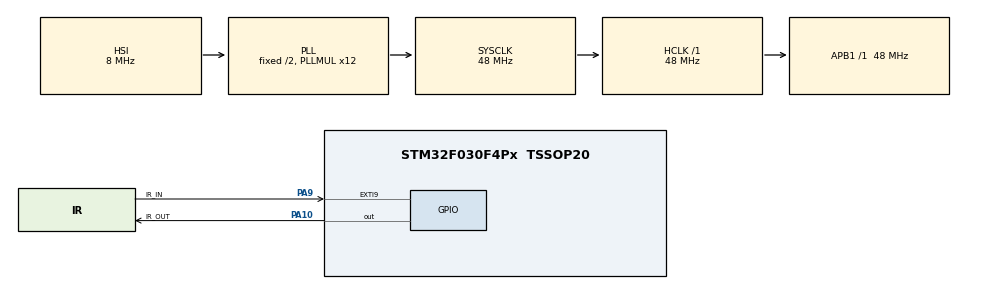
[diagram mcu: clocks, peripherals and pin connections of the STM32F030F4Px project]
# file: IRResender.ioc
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Mcu.Family=STM32F0
Mcu.Name=STM32F030F4Px
Mcu.Package=TSSOP20
NVIC.EXTI4_15_IRQn=true\:0\:0\:false\:false\:false\:true
NVIC.TIM14_IRQn=true\:0\:0\:false\:false\:false\:true
PA10.GPIO_Label=IR_OUT
PA10.GPIO_PuPd=GPIO_PULLUP
PA10.PinState=GPIO_PIN_SET
PA10.Signal=GPIO_Output
PA9.GPIO_Label=IR_IN
PA9.GPIO_ModeDefaultEXTI=GPIO_MODE_IT_RISING_FALLING
PA9.GPIO_PuPd=GPIO_PULLUP
PA9.Signal=GPXTI9
ProjectManager.HeapSize=0x200
ProjectManager.StackSize=0x400
ProjectManager.TargetToolchain=EWARM
RCC.AHBFreq_Value=48000000
RCC.APB1Freq_Value=48000000
RCC.APB1TimFreq_Value=48000000
RCC.HCLKFreq_Value=48000000
RCC.PLLMUL=RCC_PLL_MUL12
RCC.SYSCLKFreq_VALUE=48000000
RCC.SYSCLKSource=RCC_SYSCLKSOURCE_PLLCLK
TIM14.Period=3
TIM14.Prescaler=23
VP_TIM14_VS_ClockSourceINT.Mode=Enable_Timer
board=IRResender

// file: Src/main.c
/**
  ******************************************************************************
  * @file           : main.c
  * @brief          : Main program body
  ******************************************************************************
  ** This notice applies to any and all portions of this file
  * that are not between comment pairs USER CODE BEGIN and
  * USER CODE END. Other portions of this file, whether
  * inserted by the user or by software development tools
  * are owned by their respective copyright owners.
  *
  * COPYRIGHT(c) 2018 STMicroelectronics
  *
  * Redistribution and use in source and binary forms, with or without modification,
  * are permitted provided that the following conditions are met:
  *   1. Redistributions of source code must retain the above copyright notice,
  *      this list of conditions and the following disclaimer.
  *   2. Redistributions in binary form must reproduce the above copyright notice,
  *      this list of conditions and the following disclaimer in the documentation
  *      and/or other materials provided with the distribution.
  *   3. Neither the name of STMicroelectronics nor the names of its contributors
  *      may be used to endorse or promote products derived from this software
  *      without specific prior written permission.
  *
  * THIS SOFTWARE IS PROVIDED BY THE COPYRIGHT HOLDERS AND CONTRIBUTORS "AS IS"
  * AND ANY EXPRESS OR IMPLIED WARRANTIES, INCLUDING, BUT NOT LIMITED TO, THE
  * IMPLIED WARRANTIES OF MERCHANTABILITY AND FITNESS FOR A PARTICULAR PURPOSE ARE
  * DISCLAIMED. IN NO EVENT SHALL THE COPYRIGHT HOLDER OR CONTRIBUTORS BE LIABLE
  * FOR ANY DIRECT, INDIRECT, INCIDENTAL, SPECIAL, EXEMPLARY, OR CONSEQUENTIAL
  * DAMAGES (INCLUDING, BUT NOT LIMITED TO, PROCUREMENT OF SUBSTITUTE GOODS OR
  * SERVICES; LOSS OF USE, DATA, OR PROFITS; OR BUSINESS INTERRUPTION) HOWEVER
  * CAUSED AND ON ANY THEORY OF LIABILITY, WHETHER IN CONTRACT, STRICT LIABILITY,
  * OR TORT (INCLUDING NEGLIGENCE OR OTHERWISE) ARISING IN ANY WAY OUT OF THE USE
  * OF THIS SOFTWARE, EVEN IF ADVISED OF THE POSSIBILITY OF SUCH DAMAGE.
  *
  ******************************************************************************
  */
#include "main.h"
#include "stm32f0xx_hal.h"

TIM_HandleTypeDef htim14;

/* USER CODE BEGIN PV */
/* Private variables ---------------------------------------------------------*/

/* USER CODE END PV */

void SystemClock_Config(void);
static void MX_GPIO_Init(void);
static void MX_TIM14_Init(void);

/* USER CODE BEGIN PFP */
/* Private function prototypes -----------------------------------------------*/
#define IR_NEC_START_PULSE      (9000/2)
#define IR_NEC_START_WIDTH      (4500/2)

#define IR_NEC_REPEAT_PULSE      (9000/2)
#define IR_NEC_REPEAT_WIDTH      (2250/2)
#define IR_NEC_REPEAT_1_PULSE    (562/2)
#define IR_NEC_REPEAT_1_WIDTH    (96188/2)
#define IR_NEC_REPEAT_MAX_DELAY  (150000/2)

#define IR_NEC_01_PULSE         (562/2)
#define IR_NEC_0_WIDTH          (562/2)
#define IR_NEC_1_WIDTH          (1688/2)
#define IR_NEC_AFTER_PAUSE      (40500/2)

/* USER CODE END PFP */

/* USER CODE BEGIN 0 */
#define ARRAY_LENGTH(array) (sizeof((array))/sizeof((array)[0]))

int32_t times[512];
uint32_t total_read = 0;
uint32_t total_write = 0;
volatile uint32_t pulse_time = 0;
volatile uint32_t delay_timer = 0;
volatile uint32_t repeat_enabled = 0;

void DelayMicros(uint32_t us){
  delay_timer=0;
  while(delay_timer<us);
}

void AddTimeToQueue(int32_t time){
  times[total_write%ARRAY_LENGTH(times)] = time;
  total_write++;
}

int32_t GetTimeFromQueue(int32_t pos, int32_t *time){           // -1 - error
  if ((total_read+pos) < total_write){
    *time = times[(total_read+pos)%ARRAY_LENGTH(times)];
    return 0;
  }
  return -1;
}

void AddPulseToTimes(){
   AddTimeToQueue(pulse_time);
   pulse_time = 0;
}

void AddWidthToTimes(){
  AddTimeToQueue(-pulse_time);
  pulse_time = 0;
}

void TIM14_IRQHandler(void){
  __HAL_TIM_CLEAR_IT(&htim14, TIM_IT_UPDATE);
  delay_timer++;
  if (pulse_time < INT32_MAX) pulse_time++;
}

void EXTI4_15_IRQHandler(void)
{
  if(__HAL_GPIO_EXTI_GET_IT(GPIO_PIN_9) != RESET)
  {
    __HAL_GPIO_EXTI_CLEAR_IT(GPIO_PIN_9);
    if (HAL_GPIO_ReadPin(IR_IN_GPIO_Port, IR_IN_Pin) == GPIO_PIN_SET){   // если сменился с 0 на 1 то то начали измерять паузу
      AddPulseToTimes();
    } else {            // если сменился с 1 на 0 то начали измерять пульс
      AddWidthToTimes();
    }
  }
}

#define checkVal(var,val,tol) (var>(val*(100-tol)/100) && var<(val*(100+tol)/100))

int ApproximatelyEqu(uint32_t value, uint32_t etalon){
  return checkVal(value, etalon, 30);
  //uint32_t ten_percent = etalon/32;
  //if (value > etalon-ten_percent && value < etalon+ten_percent) return 1;
  //return 0;
}

uint32_t GetKeyCode(){    // return  -1 - error, -2 - key_repeat
  int32_t pulse, width;
  uint32_t ret_code = 0xFFFFFFFF;
  uint32_t keycode=0;
  int skip = 0;
  if (GetTimeFromQueue(0,&pulse)!=-1){
    if (ApproximatelyEqu(pulse,IR_NEC_START_PULSE)){  // Если пришел старт бит, иначе скипаем 1
      if (GetTimeFromQueue(1,&width)!=-1){
        width = -width;
        if (ApproximatelyEqu(width,IR_NEC_START_WIDTH)) {  // Если пришел второй бит и это код, иначе скипаем 2
          if (GetTimeFromQueue(65,&pulse)!=-1){
            for (int i=2; i<66; i+=2){
              GetTimeFromQueue(i,&pulse);
              if (ApproximatelyEqu(pulse,IR_NEC_01_PULSE)){
                GetTimeFromQueue(i+1,&width);
                width = -width;
                if (ApproximatelyEqu(width,IR_NEC_1_WIDTH)){
                  keycode |= 1 << (31-((i-2)>>1));
                } else if (ApproximatelyEqu(width,IR_NEC_0_WIDTH)){

                } else {
                  skip = 1;
                  break;
                }
              } else {
                skip = 1;
                break;
              }
            }
            if (!skip){
              skip = 66;
              ret_code = keycode;
              repeat_enabled = 1;
            }
          }
        } else if (ApproximatelyEqu(width,IR_NEC_REPEAT_WIDTH)){    // Если пришел второй бит и это повтор, иначе скипаем 2
          if (GetTimeFromQueue(2,&pulse)!=-1){
            skip = 1;
            if (ApproximatelyEqu(pulse,IR_NEC_REPEAT_1_PULSE) && repeat_enabled){
              if (GetTimeFromQueue(-1,&width)!=-1){
                skip = 3;
                width = -width;
                if (width>0 && width < IR_NEC_REPEAT_MAX_DELAY){
                  ret_code = 0xFFFFFFFE;
                } else {
                  repeat_enabled = 0;
                }
              }
            }
          }
        } else {
          skip = 1;
        }
      }
    } else {
      skip = 1;
    }
  }
  total_read+=skip;
  return ret_code;
}

void SendKeyCode(uint32_t keycode){
  HAL_GPIO_WritePin(IR_OUT_GPIO_Port, IR_OUT_Pin, GPIO_PIN_RESET);
  DelayMicros(IR_NEC_START_PULSE);
  HAL_GPIO_WritePin(IR_OUT_GPIO_Port, IR_OUT_Pin, GPIO_PIN_SET);
  DelayMicros(IR_NEC_START_WIDTH);

  uint32_t shift = 1ul<<31;
  while (shift){
    if ( keycode & shift){
      HAL_GPIO_WritePin(IR_OUT_GPIO_Port, IR_OUT_Pin, GPIO_PIN_RESET);
      DelayMicros(IR_NEC_01_PULSE);
      HAL_GPIO_WritePin(IR_OUT_GPIO_Port, IR_OUT_Pin, GPIO_PIN_SET);
      DelayMicros(IR_NEC_1_WIDTH);
    } else {
      HAL_GPIO_WritePin(IR_OUT_GPIO_Port, IR_OUT_Pin, GPIO_PIN_RESET);
      DelayMicros(IR_NEC_01_PULSE);
      HAL_GPIO_WritePin(IR_OUT_GPIO_Port, IR_OUT_Pin, GPIO_PIN_SET);
      DelayMicros(IR_NEC_0_WIDTH);
    }
    shift>>=1;
  }
  HAL_GPIO_WritePin(IR_OUT_GPIO_Port, IR_OUT_Pin, GPIO_PIN_RESET);
  DelayMicros(IR_NEC_01_PULSE);
  HAL_GPIO_WritePin(IR_OUT_GPIO_Port, IR_OUT_Pin, GPIO_PIN_SET);
  DelayMicros(IR_NEC_AFTER_PAUSE);
}

void SendKeyRepeat(){
  HAL_GPIO_WritePin(IR_OUT_GPIO_Port, IR_OUT_Pin, GPIO_PIN_RESET);
  DelayMicros(IR_NEC_REPEAT_PULSE);
  HAL_GPIO_WritePin(IR_OUT_GPIO_Port, IR_OUT_Pin, GPIO_PIN_SET);
  DelayMicros(IR_NEC_REPEAT_WIDTH);
  HAL_GPIO_WritePin(IR_OUT_GPIO_Port, IR_OUT_Pin, GPIO_PIN_RESET);
  DelayMicros(IR_NEC_REPEAT_1_PULSE);
  HAL_GPIO_WritePin(IR_OUT_GPIO_Port, IR_OUT_Pin, GPIO_PIN_SET);
  DelayMicros(IR_NEC_REPEAT_1_WIDTH);
}

/* USER CODE END 0 */

int main(void)
{

  /* MCU Configuration----------------------------------------------------------*/

  /* Reset of all peripherals, Initializes the Flash interface and the Systick. */
  HAL_Init();

  /* Configure the system clock */
  SystemClock_Config();

  /* Initialize all configured peripherals */
  MX_GPIO_Init();
  MX_TIM14_Init();
  /* USER CODE BEGIN 2 */
  HAL_Delay(100);
  HAL_TIM_Base_Start_IT(&htim14);
  /* USER CODE END 2 */

  /* Infinite loop */
  /* USER CODE BEGIN WHILE */
  while (1)
  {
    static uint32_t keycode;
    keycode = GetKeyCode();
    if (keycode != 0xFFFFFFFF){
      if (keycode == 0xFFFFFFFE){                  // Отправляем повтор
        SendKeyRepeat();
      } else {
        if (keycode == 0x5EA1D827){       //vol -
          SendKeyCode(0x61D620DF);
        } else if (keycode == 0x5EA158A7){  //vol +
          SendKeyCode(0x61D6609F);
        } else if (keycode == 0x5EA138C7){   //vol mute
          SendKeyCode(0x61D648B7);
        } else if (keycode == 0x7E8154AB){   //power
          SendKeyCode(0x61D608F7);
        } else {
          SendKeyCode(keycode);
        }
      }
    }

  /* USER CODE END WHILE */

  }

}

void SystemClock_Config(void)
{

  RCC_OscInitTypeDef RCC_OscInitStruct;
  RCC_ClkInitTypeDef RCC_ClkInitStruct;

    /**Initializes the CPU, AHB and APB busses clocks
    */
  RCC_OscInitStruct.OscillatorType = RCC_OSCILLATORTYPE_HSI;
  RCC_OscInitStruct.HSIState = RCC_HSI_ON;
  RCC_OscInitStruct.HSICalibrationValue = 16;
  RCC_OscInitStruct.PLL.PLLState = RCC_PLL_ON;
  RCC_OscInitStruct.PLL.PLLSource = RCC_PLLSOURCE_HSI;
  RCC_OscInitStruct.PLL.PLLMUL = RCC_PLL_MUL12;
  RCC_OscInitStruct.PLL.PREDIV = RCC_PREDIV_DIV1;
  if (HAL_RCC_OscConfig(&RCC_OscInitStruct) != HAL_OK)
  {
    _Error_Handler(__FILE__, __LINE__);
  }

    /**Initializes the CPU, AHB and APB busses clocks
    */
  RCC_ClkInitStruct.ClockType = RCC_CLOCKTYPE_HCLK|RCC_CLOCKTYPE_SYSCLK
                              |RCC_CLOCKTYPE_PCLK1;
  RCC_ClkInitStruct.SYSCLKSource = RCC_SYSCLKSOURCE_PLLCLK;
  RCC_ClkInitStruct.AHBCLKDivider = RCC_SYSCLK_DIV1;
  RCC_ClkInitStruct.APB1CLKDivider = RCC_HCLK_DIV1;

  if (HAL_RCC_ClockConfig(&RCC_ClkInitStruct, FLASH_LATENCY_1) != HAL_OK)
  {
    _Error_Handler(__FILE__, __LINE__);
  }

    /**Configure the Systick interrupt time
    */
  HAL_SYSTICK_Config(HAL_RCC_GetHCLKFreq()/1000);

    /**Configure the Systick
    */
  HAL_SYSTICK_CLKSourceConfig(SYSTICK_CLKSOURCE_HCLK);

  /* SysTick_IRQn interrupt configuration */
  HAL_NVIC_SetPriority(SysTick_IRQn, 0, 0);
}

/* TIM14 init function */
static void MX_TIM14_Init(void)
{

  htim14.Instance = TIM14;
  htim14.Init.Prescaler = 23;
  htim14.Init.CounterMode = TIM_COUNTERMODE_UP;
  htim14.Init.Period = 3;
  htim14.Init.ClockDivision = TIM_CLOCKDIVISION_DIV1;
  htim14.Init.AutoReloadPreload = TIM_AUTORELOAD_PRELOAD_DISABLE;
  if (HAL_TIM_Base_Init(&htim14) != HAL_OK)
  {
    _Error_Handler(__FILE__, __LINE__);
  }

}

/** Configure pins as
        * Analog
        * Input
        * Output
        * EVENT_OUT
        * EXTI
        * Free pins are configured automatically as Analog (this feature is enabled through
        * the Code Generation settings)
*/
static void MX_GPIO_Init(void)
{

  GPIO_InitTypeDef GPIO_InitStruct;

  /* GPIO Ports Clock Enable */
  __HAL_RCC_GPIOF_CLK_ENABLE();
  __HAL_RCC_GPIOA_CLK_ENABLE();
  __HAL_RCC_GPIOB_CLK_ENABLE();

  /*Configure GPIO pin Output Level */
  HAL_GPIO_WritePin(IR_OUT_GPIO_Port, IR_OUT_Pin, GPIO_PIN_SET);

  /*Configure GPIO pins : PF0 PF1 */
  GPIO_InitStruct.Pin = GPIO_PIN_0|GPIO_PIN_1;
  GPIO_InitStruct.Mode = GPIO_MODE_ANALOG;
  GPIO_InitStruct.Pull = GPIO_NOPULL;
  HAL_GPIO_Init(GPIOF, &GPIO_InitStruct);

  /*Configure GPIO pins : PA0 PA1 PA2 PA3
                           PA4 PA5 PA6 PA7
                           PA13 PA14 */
  GPIO_InitStruct.Pin = GPIO_PIN_0|GPIO_PIN_1|GPIO_PIN_2|GPIO_PIN_3
                          |GPIO_PIN_4|GPIO_PIN_5|GPIO_PIN_6|GPIO_PIN_7
                          |GPIO_PIN_13|GPIO_PIN_14;
  GPIO_InitStruct.Mode = GPIO_MODE_ANALOG;
  GPIO_InitStruct.Pull = GPIO_NOPULL;
  HAL_GPIO_Init(GPIOA, &GPIO_InitStruct);

  /*Configure GPIO pin : PB1 */
  GPIO_InitStruct.Pin = GPIO_PIN_1;
  GPIO_InitStruct.Mode = GPIO_MODE_ANALOG;
  GPIO_InitStruct.Pull = GPIO_NOPULL;
  HAL_GPIO_Init(GPIOB, &GPIO_InitStruct);

  /*Configure GPIO pin : IR_IN_Pin */
  GPIO_InitStruct.Pin = IR_IN_Pin;
  GPIO_InitStruct.Mode = GPIO_MODE_IT_RISING_FALLING;
  GPIO_InitStruct.Pull = GPIO_PULLUP;
  HAL_GPIO_Init(IR_IN_GPIO_Port, &GPIO_InitStruct);

  /*Configure GPIO pin : IR_OUT_Pin */
  GPIO_InitStruct.Pin = IR_OUT_Pin;
  GPIO_InitStruct.Mode = GPIO_MODE_OUTPUT_PP;
  GPIO_InitStruct.Pull = GPIO_PULLUP;
  GPIO_InitStruct.Speed = GPIO_SPEED_FREQ_LOW;
  HAL_GPIO_Init(IR_OUT_GPIO_Port, &GPIO_InitStruct);

  /* EXTI interrupt init*/
  HAL_NVIC_SetPriority(EXTI4_15_IRQn, 0, 0);
  HAL_NVIC_EnableIRQ(EXTI4_15_IRQn);

}

void _Error_Handler(char *file, int line)
{
  while(1)
  {
  }
}

/************************ (C) COPYRIGHT STMicroelectronics *****END OF FILE****/
